# DSP_FW_L2_NOC_CFG register map
Vendor: Texas Instruments
Peripheral module from a debugger description file (folder TDA2Px).
Registers are 32-bit, access per field, reset 0x0 unless marked. A register's access mark holds for its fields unless they carry their own. Offsets are as the file gives them; lines under a group give offsets from that group; [hi:lo] are bit positions; {n}, {i} and the like mark numbered series; 'fields as' and 'values as' point back to an identical list; <NAME> marks a mode.

## DSP_FW_L2_NOC_CFG
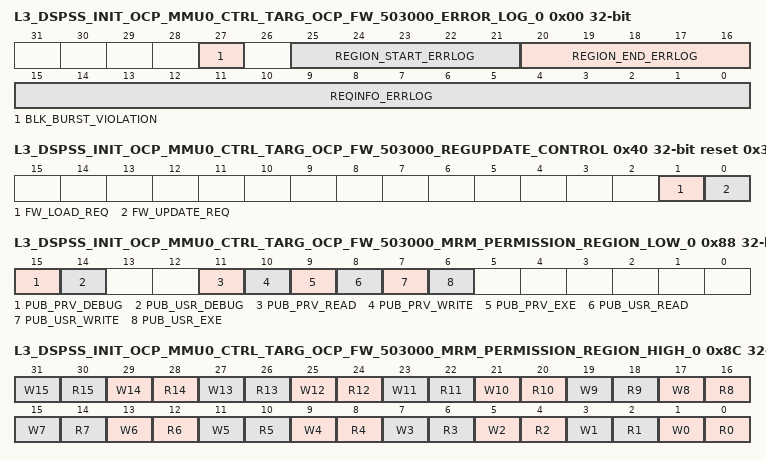
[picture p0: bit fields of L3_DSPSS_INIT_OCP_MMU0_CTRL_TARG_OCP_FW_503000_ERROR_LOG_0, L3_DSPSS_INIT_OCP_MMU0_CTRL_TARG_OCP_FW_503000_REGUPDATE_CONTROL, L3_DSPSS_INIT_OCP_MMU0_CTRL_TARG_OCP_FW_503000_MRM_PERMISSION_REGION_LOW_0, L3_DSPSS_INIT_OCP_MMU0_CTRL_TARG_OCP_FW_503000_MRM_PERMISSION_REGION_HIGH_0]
0x00 L3_DSPSS_INIT_OCP_MMU0_CTRL_TARG_OCP_FW_503000_ERROR_LOG_0 — Core 0 Error log register
  [27] BLK_BURST_VIOLATION rw — 2D burst not allowed or exceeding allowed size
  [25:21] REGION_START_ERRLOG rw — Wrong access hit this region number
  [20:16] REGION_END_ERRLOG rw — Wrong access hit this region number
  [15:0] REQINFO_ERRLOG rw — Error in reqinfo vector
0x04 L3_DSPSS_INIT_OCP_MMU0_CTRL_TARG_OCP_FW_503000_LOGICAL_ADDR_ERRLOG_0 ro — Core 0 Logical Physical Address Error log register
  [27:0] SLVOFS_LOGICAL — Address generated by the ARM before being translated
0x40 L3_DSPSS_INIT_OCP_MMU0_CTRL_TARG_OCP_FW_503000_REGUPDATE_CONTROL reset 0x3 — Register update control register
  [1] FW_LOAD_REQ rw — HW set/SW clear
  [0] FW_UPDATE_REQ rw — HW set/SW clear
0x88 L3_DSPSS_INIT_OCP_MMU0_CTRL_TARG_OCP_FW_503000_MRM_PERMISSION_REGION_LOW_0 reset 0xFFFFFFFF — MRM_PERMISSION_REGION_0_LOW register
  [15] PUB_PRV_DEBUG rw — Public Privilege Domain Debug Allowed
  [14] PUB_USR_DEBUG rw — Public User Domain Debug Allowed
  [11] PUB_PRV_READ rw — Public Privilege Read Allowed
  [10] PUB_PRV_WRITE rw — Public Privilege Write Allowed
  [9] PUB_PRV_EXE rw — Public Privilege Exe Allowed
  [8] PUB_USR_READ rw — Public User Read Access Allowed
  [7] PUB_USR_WRITE rw — Public User Write Access Allowed
  [6] PUB_USR_EXE rw — Public User Exe Access Allowed
0x8C L3_DSPSS_INIT_OCP_MMU0_CTRL_TARG_OCP_FW_503000_MRM_PERMISSION_REGION_HIGH_0 rw reset 0xFFFFFFFF — RM_PERMISSION_REGION_0_HIGH register
  [2n+1] W{n} (n=0..15) — Initiator ID{n} permission
  [2n] R{n} (n=0..15) — Initiator ID{n} permission
0x90 L3_DSPSS_INIT_OCP_MMU0_CTRL_TARG_OCP_FW_503000_START_REGION_1 — Start physical address of region 1
  [3:0] START_REGION_1 rw — Physical target start address of firewall region 1
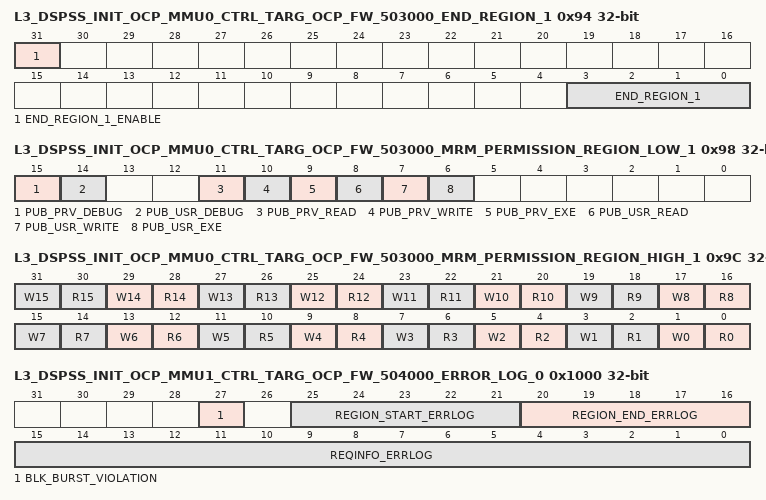
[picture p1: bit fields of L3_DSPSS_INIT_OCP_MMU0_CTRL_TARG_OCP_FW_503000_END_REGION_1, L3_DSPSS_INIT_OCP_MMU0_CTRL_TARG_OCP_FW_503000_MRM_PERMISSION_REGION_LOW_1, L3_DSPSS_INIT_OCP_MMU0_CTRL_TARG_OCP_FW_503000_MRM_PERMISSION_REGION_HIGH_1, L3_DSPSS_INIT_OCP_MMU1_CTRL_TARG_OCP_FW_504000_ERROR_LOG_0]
0x94 L3_DSPSS_INIT_OCP_MMU0_CTRL_TARG_OCP_FW_503000_END_REGION_1 — End physical address of region 1
  [31] END_REGION_1_ENABLE rw
  [3:0] END_REGION_1 rw — Physical target end address of firewall region 1
0x98 L3_DSPSS_INIT_OCP_MMU0_CTRL_TARG_OCP_FW_503000_MRM_PERMISSION_REGION_LOW_1 reset 0xFFFFFFFF — RM_PERMISSION_REGION_1_LOW register
  fields as L3_DSPSS_INIT_OCP_MMU0_CTRL_TARG_OCP_FW_503000_MRM_PERMISSION_REGION_LOW_0
0x9C L3_DSPSS_INIT_OCP_MMU0_CTRL_TARG_OCP_FW_503000_MRM_PERMISSION_REGION_HIGH_1 rw reset 0xFFFFFFFF — RM_PERMISSION_REGION_1_HIGH register
  fields as L3_DSPSS_INIT_OCP_MMU0_CTRL_TARG_OCP_FW_503000_MRM_PERMISSION_REGION_HIGH_0
0x1000 L3_DSPSS_INIT_OCP_MMU1_CTRL_TARG_OCP_FW_504000_ERROR_LOG_0 — Core 0 Error log register
  fields as L3_DSPSS_INIT_OCP_MMU0_CTRL_TARG_OCP_FW_503000_ERROR_LOG_0
0x1004 L3_DSPSS_INIT_OCP_MMU1_CTRL_TARG_OCP_FW_504000_LOGICAL_ADDR_ERRLOG_0 ro — Core 0 Logical Physical Address Error log register
  fields as L3_DSPSS_INIT_OCP_MMU0_CTRL_TARG_OCP_FW_503000_LOGICAL_ADDR_ERRLOG_0
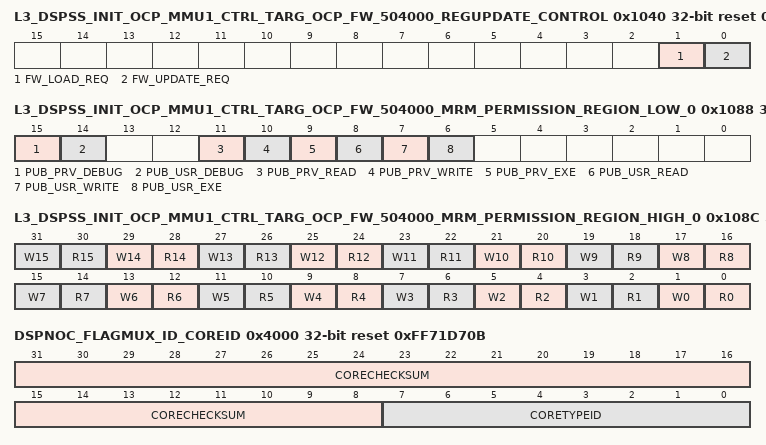
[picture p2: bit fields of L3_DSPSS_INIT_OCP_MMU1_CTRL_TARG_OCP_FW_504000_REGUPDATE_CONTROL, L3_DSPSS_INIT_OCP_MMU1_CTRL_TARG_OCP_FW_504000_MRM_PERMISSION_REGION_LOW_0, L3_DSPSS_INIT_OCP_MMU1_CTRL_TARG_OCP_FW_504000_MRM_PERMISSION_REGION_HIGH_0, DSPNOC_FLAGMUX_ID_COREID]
0x1040 L3_DSPSS_INIT_OCP_MMU1_CTRL_TARG_OCP_FW_504000_REGUPDATE_CONTROL reset 0x3 — Register update control register
  fields as L3_DSPSS_INIT_OCP_MMU0_CTRL_TARG_OCP_FW_503000_REGUPDATE_CONTROL
0x1088 L3_DSPSS_INIT_OCP_MMU1_CTRL_TARG_OCP_FW_504000_MRM_PERMISSION_REGION_LOW_0 reset 0xFFFFFFFF — RM_PERMISSION_REGION_0_LOW register
  fields as L3_DSPSS_INIT_OCP_MMU0_CTRL_TARG_OCP_FW_503000_MRM_PERMISSION_REGION_LOW_0
0x108C L3_DSPSS_INIT_OCP_MMU1_CTRL_TARG_OCP_FW_504000_MRM_PERMISSION_REGION_HIGH_0 rw reset 0xFFFFFFFF — RM_PERMISSION_REGION_0_HIGH register
  fields as L3_DSPSS_INIT_OCP_MMU0_CTRL_TARG_OCP_FW_503000_MRM_PERMISSION_REGION_HIGH_0
0x4000 DSPNOC_FLAGMUX_ID_COREID ro reset 0xFF71D70B
  [31:8] CORECHECKSUM — Field containing a checksum of the parameters of the IP.
  [7:0] CORETYPEID — Field identifying the type of IP.
0x4004 DSPNOC_FLAGMUX_ID_REVISIONID ro reset not defined
  [31:0] REVISION — IP Revision.
0x4008 DSPNOC_FLAGMUX_FAULTEN reset 0x1
  [0] FAULTEN rw — Global Fault Enable register
0x400C DSPNOC_FLAGMUX_FAULTSTATUS ro
  [0] FAULTSTATUS — Global Fault Status register
0x4010 DSPNOC_FLAGMUX_FLAGINEN0 reset 0x1
  [0] FLAGINEN0 rw — FlagIn Enable register #0
0x4014 DSPNOC_FLAGMUX_FLAGINSTATUS0 ro
  [0] FLAGINSTATUS0 — FlagIn Status register #0
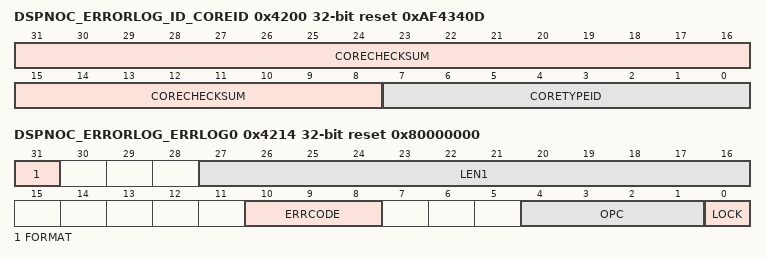
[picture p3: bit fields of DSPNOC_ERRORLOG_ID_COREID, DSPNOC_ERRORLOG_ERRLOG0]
0x4200 DSPNOC_ERRORLOG_ID_COREID ro reset 0xAF4340D
  fields as DSPNOC_FLAGMUX_ID_COREID
0x4204 DSPNOC_ERRORLOG_ID_REVISIONID ro reset not defined
  [31:0] REVISION — IP Revision.
0x4208 DSPNOC_ERRORLOG_FAULTEN reset 0x1
  [0] FAULTEN rw — Enable Fault output
0x420C DSPNOC_ERRORLOG_ERRVLD ro
  [0] ERRVLD — Error logged Valid
0x4210 DSPNOC_ERRORLOG_ERRCLR
  [0] ERRCLR rw — Clr ErrVld status
0x4214 DSPNOC_ERRORLOG_ERRLOG0 ro reset 0x80000000 — Header: Lock, Opcode, Len1, ErrCode values
  [31] FORMAT — Format of ErrLog0 register
  [27:16] LEN1 — Header: Len1 value
  [10:8] ERRCODE — Header: Error Code value
  [4:1] OPC — Header: Opcode value
  [0] LOCK — Header: Lock bit value
0x4218 DSPNOC_ERRORLOG_ERRLOG1 ro
  [14:0] ERRLOG1 — Header: RouteId lsb value
0x4220 DSPNOC_ERRORLOG_ERRLOG3 ro
  [30:0] ERRLOG3 — Header: Addr lsb value
0x4228 DSPNOC_ERRORLOG_ERRLOG5 ro
  [21:0] ERRLOG5 — Header: User lsb value
